# ms32c000axx register map
Vendor: MS; Series: MS32C; File version: 1.0.0
CPU: CM0+ r0p1, little endian, no MPU, no FPU, 4 interrupt priority bits
Registers are 32-bit, read-write, reset 0x0 unless marked. A register's access mark holds for its fields unless they carry their own. Offsets are from the block's base; [hi:lo] are bit positions; {n}, {i} and the like mark numbered series.

## GPIOA — General-purpose I/Os
Base 0x50000000
Same registers: GPIOB 0x50000400
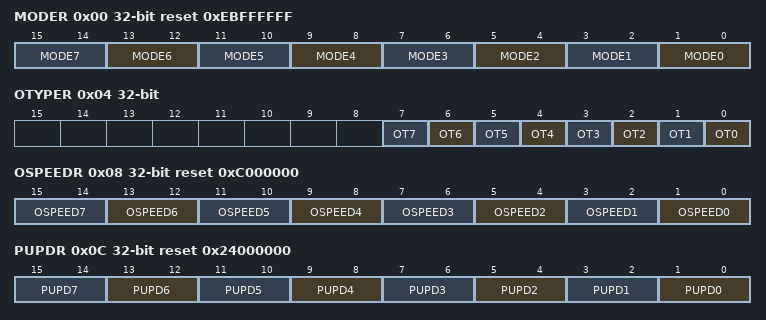
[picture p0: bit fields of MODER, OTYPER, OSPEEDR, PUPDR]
0x00 MODER reset 0xEBFFFFFF — GPIO port mode register
  [2n+1:2n] MODE{n} (n=0..7) — Port x configuration bits (y = 0..15)
0x04 OTYPER — GPIO port output type register
  [n] OT{n} (n=0..7) — Port x configuration bits (y = 0..15)
0x08 OSPEEDR reset 0xC000000 — GPIO port output speed register
  [2n+1:2n] OSPEED{n} (n=0..7) — Port x configuration bits (y = 0..15)
0x0C PUPDR reset 0x24000000 — GPIO port pull-up/pull-down register
  [2n+1:2n] PUPD{n} (n=0..7) — Port x configuration bits (y = 0..15)
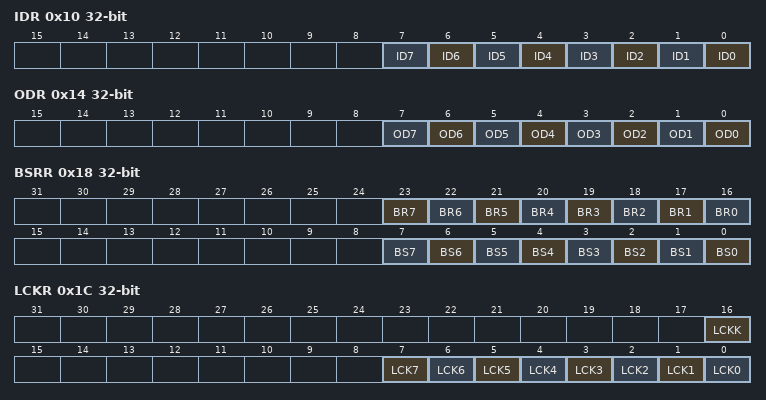
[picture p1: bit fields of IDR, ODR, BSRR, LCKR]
0x10 IDR ro — GPIO port input data register
  [n] ID{n} (n=0..7) — Port input data (y = 0..15)
0x14 ODR — GPIO port output data register
  [n] OD{n} (n=0..7) — Port output data (y = 0..15)
0x18 BSRR wo — GPIO port bit set/reset register
  [n+16] BR{n} (n=1..7) — Port x reset bit y (y = 0..15)
  [16] BR0 — Port x set bit y (y= 0..15)
  [n] BS{n} (n=0..7) — Port x set bit y (y= 0..15)
0x1C LCKR — GPIO port configuration lock register
  [16] LCKK — Port x lock bit y (y= 0..15)
  [n] LCK{n} (n=0..7) — Port x lock bit y (y= 0..15)
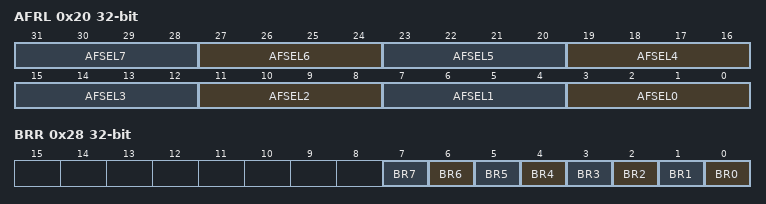
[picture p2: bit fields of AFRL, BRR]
0x20 AFRL — GPIO alternate function low register
  [4n+3:4n] AFSEL{n} (n=0..7) — Alternate function selection for port x bit y (y = 0..7)
0x28 BRR wo — port bit reset register
  [n] BR{n} (n=0..7) — Port Reset bit

## GPIOC — General-purpose I/Os
Base 0x50000800
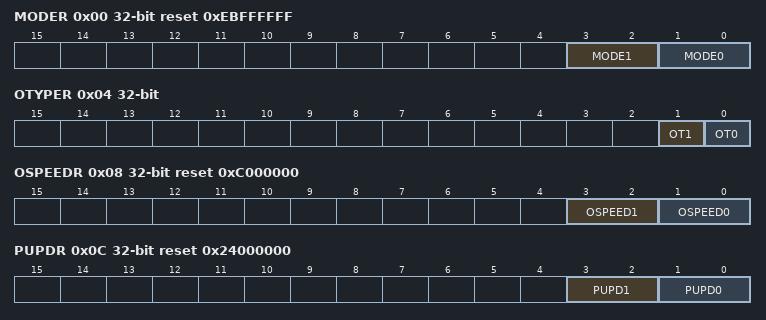
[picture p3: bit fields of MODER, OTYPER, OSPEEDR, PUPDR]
0x00 MODER reset 0xEBFFFFFF — GPIO port mode register
  [3:2] MODE1 — Port x configuration bits (y = 0..15)
  [1:0] MODE0 — Port x configuration bits (y = 0..15)
0x04 OTYPER — GPIO port output type register
  [1] OT1 — Port x configuration bits (y = 0..15)
  [0] OT0 — Port x configuration bits (y = 0..15)
0x08 OSPEEDR reset 0xC000000 — GPIO port output speed register
  [3:2] OSPEED1 — Port x configuration bits (y = 0..15)
  [1:0] OSPEED0 — Port x configuration bits (y = 0..15)
0x0C PUPDR reset 0x24000000 — GPIO port pull-up/pull-down register
  [3:2] PUPD1 — Port x configuration bits (y = 0..15)
  [1:0] PUPD0 — Port x configuration bits (y = 0..15)
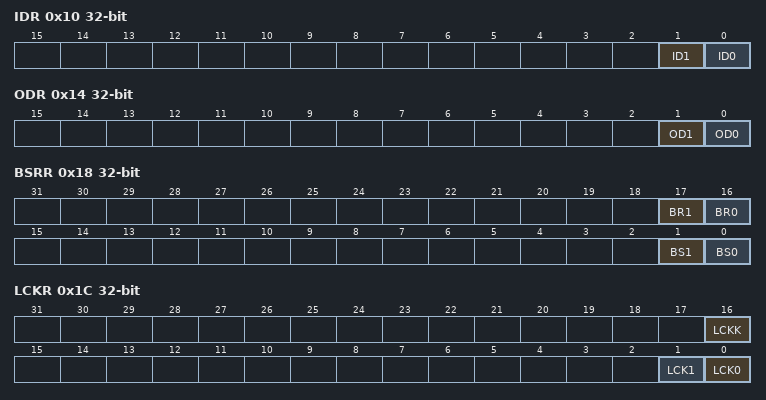
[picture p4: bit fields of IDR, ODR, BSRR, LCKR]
0x10 IDR ro — GPIO port input data register
  [1] ID1 — Port input data (y = 0..15)
  [0] ID0 — Port input data (y = 0..15)
0x14 ODR — GPIO port output data register
  [1] OD1 — Port output data (y = 0..15)
  [0] OD0 — Port output data (y = 0..15)
0x18 BSRR wo — GPIO port bit set/reset register
  [17] BR1 — Port x reset bit y (y = 0..15)
  [16] BR0 — Port x set bit y (y= 0..15)
  [1] BS1 — Port x set bit y (y= 0..15)
  [0] BS0 — Port x set bit y (y= 0..15)
0x1C LCKR — GPIO port configuration lock register
  [16] LCKK — Port x lock bit y (y= 0..15)
  [1] LCK1 — Port x lock bit y (y= 0..15)
  [0] LCK0 — Port x lock bit y (y= 0..15)
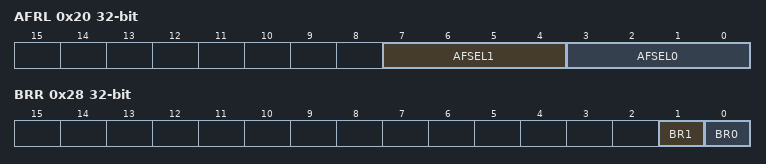
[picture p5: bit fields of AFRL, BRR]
0x20 AFRL — GPIO alternate function low register
  [7:4] AFSEL1 — Alternate function selection for port x bit y (y = 0..7)
  [3:0] AFSEL0 — Alternate function selection for port x bit y (y = 0..7)
0x28 BRR wo — port bit reset register
  [1] BR1 — Port Reset bit
  [0] BR0 — Port Reset bit

## IWDG — Independent watchdog
Base 0x40003000
0x00 KR wo — Key register (IWDG_KR)
  [15:0] KEY — Key value
0x04 PR — Prescaler register (IWDG_PR)
  [2:0] PR — Prescaler divider
0x08 RLR reset 0xFFF — Reload register (IWDG_RLR)
  [11:0] RL — Watchdog counter reload value
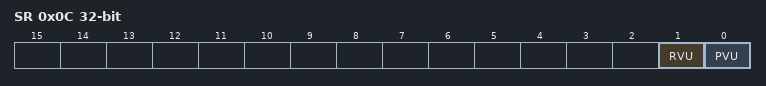
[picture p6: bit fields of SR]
0x0C SR ro — Status register (IWDG_SR)
  [1] RVU — Watchdog counter reload value update
  [0] PVU — Watchdog prescaler value update

## LPTIM1 — Low power timer
Base 0x40007C00
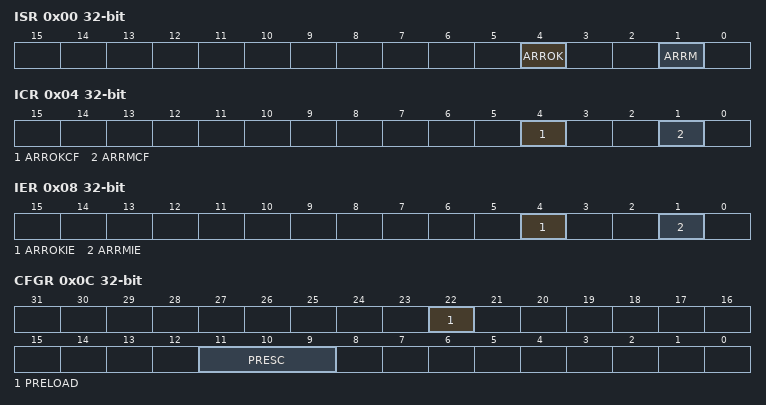
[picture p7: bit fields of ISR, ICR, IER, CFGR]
0x00 ISR ro — Interrupt and Status Register
  [4] ARROK — Autoreload match update OK
  [1] ARRM — Autoreload match
0x04 ICR wo — Interrupt Clear Register
  [4] ARROKCF — Autoreload match update OK Clear Flag
  [1] ARRMCF — Autoreload match Clear Flag
0x08 IER — Interrupt Enable Register
  [4] ARROKIE — Autoreload match update OK Interrupt Enable
  [1] ARRMIE — Autoreload matchInterrupt Enable
0x0C CFGR — Configuration Register
  [22] PRELOAD — Registers update mode
  [11:9] PRESC — Clock prescaler
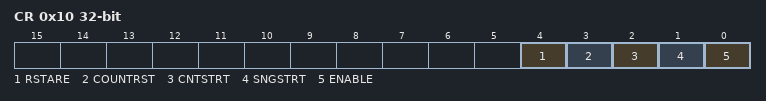
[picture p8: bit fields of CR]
0x10 CR — Control Register
  [4] RSTARE — Reset after read enable
  [3] COUNTRST — Reset counter
  [2] CNTSTRT
  [1] SNGSTRT — LPTIM start in single mode
  [0] ENABLE — LPTIM Enable
0x18 ARR reset 0x1 — Autoreload Register
  [15:0] ARR — Auto reload value
0x1C CNT ro — Counter Register
  [15:0] CNT — Counter value
